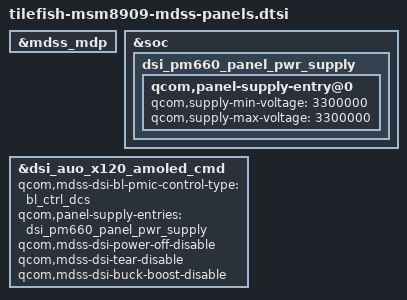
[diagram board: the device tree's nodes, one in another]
/* Copyright (c) 2014-2018, The Linux Foundation. All rights reserved.
 *
 * This program is free software; you can redistribute it and/or modify
 * it under the terms of the GNU General Public License version 2 and
 * only version 2 as published by the Free Software Foundation.
 *
 * This program is distributed in the hope that it will be useful,
 * but WITHOUT ANY WARRANTY; without even the implied warranty of
 * MERCHANTABILITY or FITNESS FOR A PARTICULAR PURPOSE.  See the
 * GNU General Public License for more details.
 */

#include "tilefish-dsi-panel-auo-x120-amoled-cmd.dtsi"

&mdss_mdp {
	/delete-node/ qcom,mdss_dsi_auo_390p_cmd;
};

&soc {
	dsi_pm660_panel_pwr_supply {
		qcom,panel-supply-entry@0 {
			/delete-property/ qcom,supply-min-voltage;
			/delete-property/ qcom,supply-max-voltage;
			qcom,supply-min-voltage = <3300000>;
			qcom,supply-max-voltage = <3300000>;
		};
	};
};

&dsi_auo_x120_amoled_cmd {
	qcom,mdss-dsi-bl-pmic-control-type = "bl_ctrl_dcs";
	qcom,panel-supply-entries = <&dsi_pm660_panel_pwr_supply>;
	qcom,mdss-dsi-power-off-disable;
	qcom,mdss-dsi-tear-disable;
	qcom,mdss-dsi-buck-boost-disable;
};
